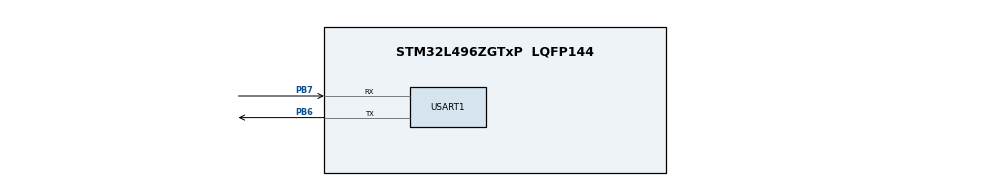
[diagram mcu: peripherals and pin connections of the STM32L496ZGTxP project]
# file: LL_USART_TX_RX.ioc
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Mcu.Family=STM32L4
Mcu.Name=STM32L496ZGTxP
Mcu.Package=LQFP144
NVIC.PriorityGroup=NVIC_PRIORITYGROUP_4
PB6.Mode=Asynchronous
PB6.Signal=USART1_TX
PB7.Mode=Asynchronous
PB7.Signal=USART1_RX
PH0-OSC_IN\ (PH0).Mode=HSE-External-Oscillator
PH0-OSC_IN\ (PH0).Signal=RCC_OSC_IN
PH1-OSC_OUT\ (PH1).Mode=HSE-External-Oscillator
PH1-OSC_OUT\ (PH1).Signal=RCC_OSC_OUT
ProjectManager.HeapSize=0x200
ProjectManager.StackSize=0x400
ProjectManager.TargetToolchain=STM32CubeIDE
RCC.48MHZClocksFreq_Value=24000000
RCC.ADCFreq_Value=160000000
RCC.AHBFreq_Value=64000000
RCC.APB1CLKDivider=RCC_HCLK_DIV2
RCC.APB1Freq_Value=32000000
RCC.APB1TimFreq_Value=64000000
RCC.APB2CLKDivider=RCC_HCLK_DIV4
RCC.APB2Freq_Value=16000000
RCC.APB2TimFreq_Value=32000000
RCC.CortexFreq_Value=64000000
RCC.HCLKFreq_Value=64000000
RCC.HSE_VALUE=8000000
RCC.HSI48_VALUE=48000000
RCC.HSI_VALUE=16000000
RCC.LSE_VALUE=32768
RCC.MSIClockRange=RCC_MSIRANGE_9
RCC.MSI_VALUE=24000000
RCC.PLLMUL=RCC_PLL_MUL9
RCC.PLLSAI1N=20
RCC.PLLSourceVirtual=RCC_PLLSOURCE_HSI
RCC.PRESCALERUSB=RCC_USBCLKSOURCE_PLL_DIV1_5
RCC.SYSCLKFreq_VALUE=64000000
RCC.SYSCLKSource=RCC_SYSCLKSOURCE_PLLCLK
RCC.SYSCLKSourceVirtual=RCC_SYSCLKSOURCE_PLLCLK
RCC.USBFreq_Value=160000000
RCC.VCOOutputFreq_Value=128000000
USART1.VirtualMode-Asynchronous=VM_ASYNC
VP_TIM16_VS_ClockSourceINT.Mode=Enable_Timer
board=NUCLEO-L496ZG-P

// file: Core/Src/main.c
/* USER CODE BEGIN Header */
/**
  ******************************************************************************
  * @file           : main.c
  * @brief          : Main program body
  ******************************************************************************
  * @attention
  *
  * Copyright (c) 2024 STMicroelectronics.
  * All rights reserved.
  *
  * This software is licensed under terms that can be found in the LICENSE file
  * in the root directory of this software component.
  * If no LICENSE file comes with this software, it is provided AS-IS.
  *
  ******************************************************************************
  */
/* USER CODE END Header */
#include "main.h"

/* USER CODE BEGIN Includes */
#include "my_uart.h"
#include"my_timer.h"
#include<string.h>
#include<stdio.h>
/* USER CODE END Includes */

/* USER CODE BEGIN PV */
usart_handle_t usart_dev = {.handle = USART1,};

usart_handle_t *dev = &usart_dev;

/* USER CODE END PV */

void SystemClock_Config(void);
static void MX_GPIO_Init(void);
static void MX_USART1_UART_Init(void);
static void MX_TIM16_Init(void);

int main(void)
{

  /* USER CODE BEGIN 1 */
	//uint8_t buf[50];
  /* USER CODE END 1 */

  /* MCU Configuration--------------------------------------------------------*/

  /* Reset of all peripherals, Initializes the Flash interface and the Systick. */
  LL_APB2_GRP1_EnableClock(LL_APB2_GRP1_PERIPH_SYSCFG);
  LL_APB1_GRP1_EnableClock(LL_APB1_GRP1_PERIPH_PWR);

  /* System interrupt init*/
  NVIC_SetPriorityGrouping(NVIC_PRIORITYGROUP_4);

  /* USER CODE BEGIN Init */
  MY_TIMER_Init();
  /* Enable clock for GPIOC first*/
  	LL_AHB2_GRP1_EnableClock (LL_AHB2_GRP1_PERIPH_GPIOC);

  	/* Now declare pin PC7 as output pin*/
  	LL_GPIO_SetPinMode (GPIOC,LL_GPIO_PIN_7 , LL_GPIO_MODE_OUTPUT);

  	/* Set PC13 as input pin */
  	LL_GPIO_SetPinMode (GPIOC,LL_GPIO_PIN_13 , LL_GPIO_MODE_INPUT);
  /* USER CODE END Init */

  /* Configure the system clock */
  SystemClock_Config();

  /* Initialize all configured peripherals */
  MX_GPIO_Init();
  MX_USART1_UART_Init();
  MX_TIM16_Init();
  /* USER CODE BEGIN 2 */
//  strcpy((char*)buf,"Application is Running\r\n");
  char buf[50] = "Application is running\r\n";
  uart_write(dev->handle,buf);

  /* USER CODE END 2 */

  /* Infinite loop */
  while (1)
  {

    /* USER CODE BEGIN 3 */
	  if(LL_GPIO_IsInputPinSet(GPIOC, LL_GPIO_PIN_13)){
		  MY_Delay(10000);
		  strcpy((char*)buf,"In the loop\r\n");
		   uart_write(dev->handle,buf);
		   MY_Delay(1000);
	  }

  }
  /* USER CODE END 3 */
}

void SystemClock_Config(void)
{
  LL_FLASH_SetLatency(LL_FLASH_LATENCY_3);
  while(LL_FLASH_GetLatency()!= LL_FLASH_LATENCY_3)
  {
  }
  LL_PWR_SetRegulVoltageScaling(LL_PWR_REGU_VOLTAGE_SCALE1);
  while (LL_PWR_IsActiveFlag_VOS() != 0)
  {
  }
  LL_RCC_HSI_Enable();

   /* Wait till HSI is ready */
  while(LL_RCC_HSI_IsReady() != 1)
  {

  }
  LL_RCC_HSI_SetCalibTrimming(64);
  LL_RCC_PLL_ConfigDomain_SYS(LL_RCC_PLLSOURCE_HSI, LL_RCC_PLLM_DIV_1, 8, LL_RCC_PLLR_DIV_2);
  LL_RCC_PLL_EnableDomain_SYS();
  LL_RCC_PLL_Enable();

   /* Wait till PLL is ready */
  while(LL_RCC_PLL_IsReady() != 1)
  {

  }
  LL_RCC_SetSysClkSource(LL_RCC_SYS_CLKSOURCE_PLL);

   /* Wait till System clock is ready */
  while(LL_RCC_GetSysClkSource() != LL_RCC_SYS_CLKSOURCE_STATUS_PLL)
  {

  }
  LL_RCC_SetAHBPrescaler(LL_RCC_SYSCLK_DIV_1);
  LL_RCC_SetAPB1Prescaler(LL_RCC_APB1_DIV_2);
  LL_RCC_SetAPB2Prescaler(LL_RCC_APB2_DIV_4);

  LL_Init1msTick(64000000);

  LL_SetSystemCoreClock(64000000);
}

static void MX_TIM16_Init(void)
{

  LL_TIM_InitTypeDef TIM_InitStruct = {0};

  /* Peripheral clock enable */
  LL_APB2_GRP1_EnableClock(LL_APB2_GRP1_PERIPH_TIM16);

  TIM_InitStruct.Prescaler = 0;
  TIM_InitStruct.CounterMode = LL_TIM_COUNTERMODE_UP;
  TIM_InitStruct.Autoreload = 65535;
  TIM_InitStruct.ClockDivision = LL_TIM_CLOCKDIVISION_DIV1;
  TIM_InitStruct.RepetitionCounter = 0;
  LL_TIM_Init(TIM16, &TIM_InitStruct);
  LL_TIM_DisableARRPreload(TIM16);

}

static void MX_USART1_UART_Init(void)
{

  LL_USART_InitTypeDef USART_InitStruct = {0};

  LL_GPIO_InitTypeDef GPIO_InitStruct = {0};

  LL_RCC_SetUSARTClockSource(LL_RCC_USART1_CLKSOURCE_PCLK2);

  /* Peripheral clock enable */
  LL_APB2_GRP1_EnableClock(LL_APB2_GRP1_PERIPH_USART1);

  LL_AHB2_GRP1_EnableClock(LL_AHB2_GRP1_PERIPH_GPIOB);
  /**USART1 GPIO Configuration
  PB6   ------> USART1_TX
  PB7   ------> USART1_RX
  */
  GPIO_InitStruct.Pin = LL_GPIO_PIN_6|LL_GPIO_PIN_7;
  GPIO_InitStruct.Mode = LL_GPIO_MODE_ALTERNATE;
  GPIO_InitStruct.Speed = LL_GPIO_SPEED_FREQ_VERY_HIGH;
  GPIO_InitStruct.OutputType = LL_GPIO_OUTPUT_PUSHPULL;
  GPIO_InitStruct.Pull = LL_GPIO_PULL_NO;
  GPIO_InitStruct.Alternate = LL_GPIO_AF_7;
  LL_GPIO_Init(GPIOB, &GPIO_InitStruct);

  USART_InitStruct.BaudRate = 115200;
  USART_InitStruct.DataWidth = LL_USART_DATAWIDTH_8B;
  USART_InitStruct.StopBits = LL_USART_STOPBITS_1;
  USART_InitStruct.Parity = LL_USART_PARITY_NONE;
  USART_InitStruct.TransferDirection = LL_USART_DIRECTION_TX_RX;
  USART_InitStruct.HardwareFlowControl = LL_USART_HWCONTROL_NONE;
  USART_InitStruct.OverSampling = LL_USART_OVERSAMPLING_16;
  LL_USART_Init(USART1, &USART_InitStruct);
  LL_USART_ConfigAsyncMode(USART1);
  LL_USART_Enable(USART1);

}

static void MX_GPIO_Init(void)
{

  /* GPIO Ports Clock Enable */
  LL_AHB2_GRP1_EnableClock(LL_AHB2_GRP1_PERIPH_GPIOH);
  LL_AHB2_GRP1_EnableClock(LL_AHB2_GRP1_PERIPH_GPIOB);

}

void Error_Handler(void)
{
  __disable_irq();
  while (1)
  {
  }
}
